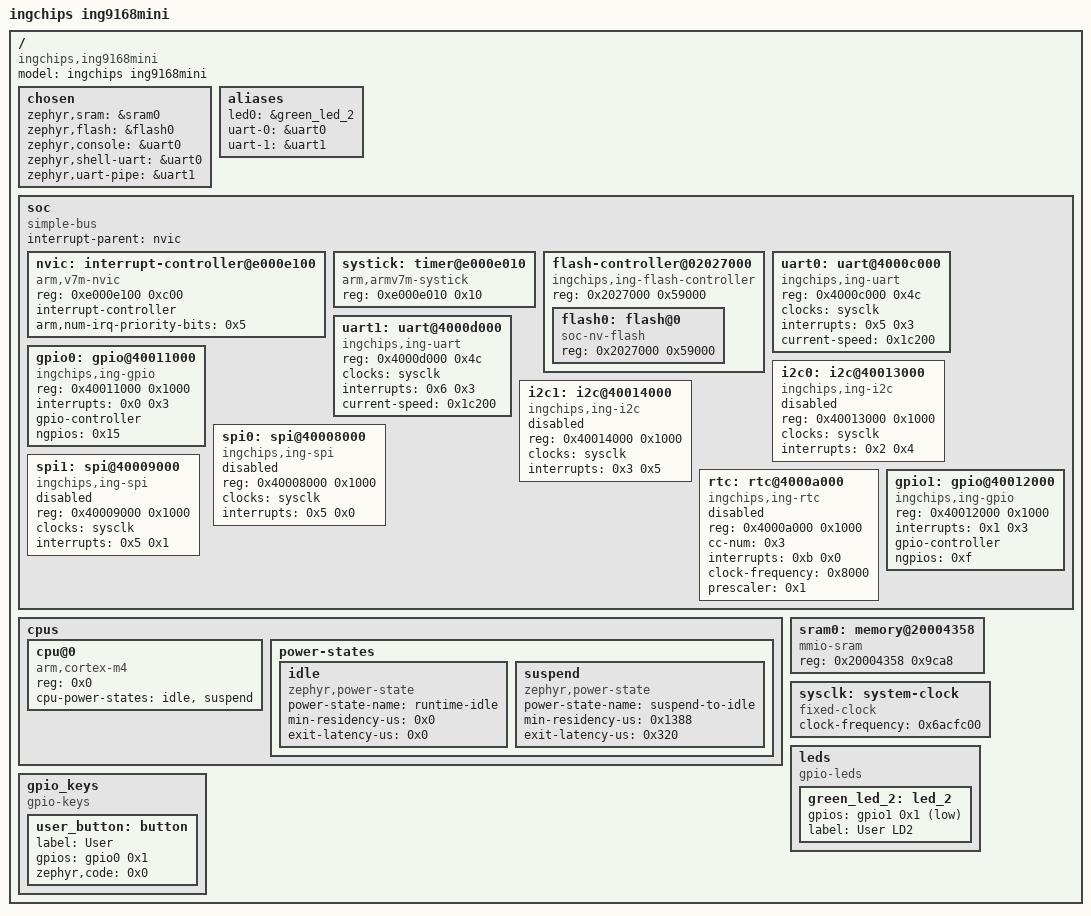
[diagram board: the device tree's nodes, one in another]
/dts-v1/;

/ {
	#address-cells = < 0x1 >;
	#size-cells = < 0x1 >;
	model = "ingchips ing9168mini";
	compatible = "ingchips,ing9168mini";
	chosen {
		zephyr,sram = &sram0;
		zephyr,flash = &flash0;
		zephyr,console = &uart0;
		zephyr,shell-uart = &uart0;
		zephyr,uart-pipe = &uart1;
	};
	aliases {
		led0 = &green_led_2;
		uart-0 = &uart0;
		uart-1 = &uart1;
	};
	soc {
		#address-cells = < 0x1 >;
		#size-cells = < 0x1 >;
		compatible = "simple-bus";
		interrupt-parent = < &nvic >;
		ranges;
		nvic: interrupt-controller@e000e100 {
			#address-cells = < 0x1 >;
			compatible = "arm,v7m-nvic";
			reg = < 0xe000e100 0xc00 >;
			interrupt-controller;
			#interrupt-cells = < 0x2 >;
			arm,num-irq-priority-bits = < 0x5 >;
			phandle = < 0x1 >;
		};
		systick: timer@e000e010 {
			compatible = "arm,armv7m-systick";
			reg = < 0xe000e010 0x10 >;
		};
		flash-controller@02027000 {
			compatible = "ingchips,ing-flash-controller";
			reg = < 0x2027000 0x59000 >;
			#address-cells = < 0x1 >;
			#size-cells = < 0x1 >;
			flash0: flash@0 {
				compatible = "soc-nv-flash";
				reg = < 0x2027000 0x59000 >;
			};
		};
		uart0: uart@4000c000 {
			compatible = "ingchips,ing-uart";
			reg = < 0x4000c000 0x4c >;
			clocks = < &sysclk >;
			interrupts = < 0x5 0x3 >;
			status = "okay";
			current-speed = < 0x1c200 >;
		};
		uart1: uart@4000d000 {
			compatible = "ingchips,ing-uart";
			reg = < 0x4000d000 0x4c >;
			clocks = < &sysclk >;
			interrupts = < 0x6 0x3 >;
			status = "okay";
			current-speed = < 0x1c200 >;
		};
		gpio0: gpio@40011000 {
			compatible = "ingchips,ing-gpio";
			reg = < 0x40011000 0x1000 >;
			interrupts = < 0x0 0x3 >;
			gpio-controller;
			#gpio-cells = < 0x2 >;
			ngpios = < 0x15 >;
			status = "okay";
			phandle = < 0x6 >;
		};
		i2c0: i2c@40013000 {
			compatible = "ingchips,ing-i2c";
			#address-cells = < 0x1 >;
			#size-cells = < 0x0 >;
			reg = < 0x40013000 0x1000 >;
			clocks = < &sysclk >;
			interrupts = < 0x2 0x4 >;
			status = "disabled";
		};
		i2c1: i2c@40014000 {
			compatible = "ingchips,ing-i2c";
			#address-cells = < 0x1 >;
			#size-cells = < 0x0 >;
			reg = < 0x40014000 0x1000 >;
			clocks = < &sysclk >;
			interrupts = < 0x3 0x5 >;
			status = "disabled";
		};
		spi0: spi@40008000 {
			compatible = "ingchips,ing-spi";
			#address-cells = < 0x1 >;
			#size-cells = < 0x0 >;
			reg = < 0x40008000 0x1000 >;
			clocks = < &sysclk >;
			interrupts = < 0x5 0x0 >;
			status = "disabled";
		};
		spi1: spi@40009000 {
			compatible = "ingchips,ing-spi";
			#address-cells = < 0x1 >;
			#size-cells = < 0x0 >;
			reg = < 0x40009000 0x1000 >;
			clocks = < &sysclk >;
			interrupts = < 0x5 0x1 >;
			status = "disabled";
		};
		rtc: rtc@4000a000 {
			compatible = "ingchips,ing-rtc";
			reg = < 0x4000a000 0x1000 >;
			cc-num = < 0x3 >;
			interrupts = < 0xb 0x0 >;
			status = "disabled";
			clock-frequency = < 0x8000 >;
			prescaler = < 0x1 >;
		};
		gpio1: gpio@40012000 {
			compatible = "ingchips,ing-gpio";
			reg = < 0x40012000 0x1000 >;
			interrupts = < 0x1 0x3 >;
			gpio-controller;
			#gpio-cells = < 0x2 >;
			ngpios = < 0xf >;
			status = "okay";
			phandle = < 0x5 >;
		};
	};
	cpus {
		#address-cells = < 0x1 >;
		#size-cells = < 0x0 >;
		cpu@0 {
			device_type = "cpu";
			compatible = "arm,cortex-m4";
			reg = < 0x0 >;
			cpu-power-states = < &idle &suspend >;
		};
		power-states {
			idle: idle {
				compatible = "zephyr,power-state";
				power-state-name = "runtime-idle";
				min-residency-us = < 0x0 >;
				exit-latency-us = < 0x0 >;
				phandle = < 0x3 >;
			};
			suspend: suspend {
				compatible = "zephyr,power-state";
				power-state-name = "suspend-to-idle";
				min-residency-us = < 0x1388 >;
				exit-latency-us = < 0x320 >;
				phandle = < 0x4 >;
			};
		};
	};
	sram0: memory@20004358 {
		compatible = "mmio-sram";
		reg = < 0x20004358 0x9ca8 >;
	};
	sysclk: system-clock {
		compatible = "fixed-clock";
		clock-frequency = < 0x6acfc00 >;
		#clock-cells = < 0x0 >;
		phandle = < 0x2 >;
	};
	leds: leds {
		compatible = "gpio-leds";
		green_led_2: led_2 {
			gpios = < &gpio1 0x1 0x1 >;
			label = "User LD2";
		};
	};
	gpio_keys {
		compatible = "gpio-keys";
		user_button: button {
			label = "User";
			gpios = < &gpio0 0x1 0x0 >;
			zephyr,code = < 0x0 >;
		};
	};
};
